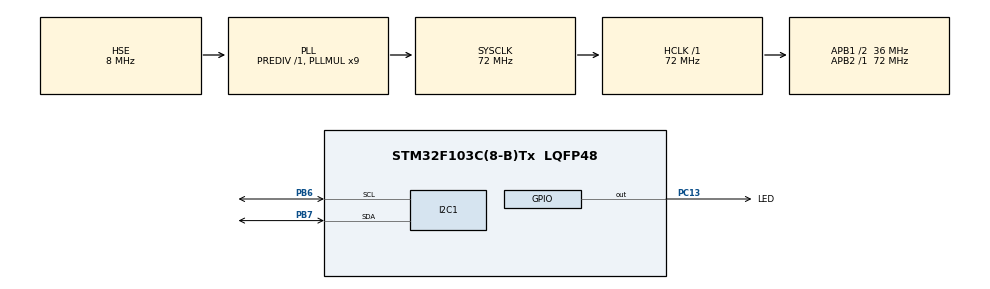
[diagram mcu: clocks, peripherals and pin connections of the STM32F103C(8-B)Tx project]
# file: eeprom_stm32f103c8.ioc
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I2C1.I2C_Mode=I2C_Fast
Mcu.Family=STM32F1
Mcu.Name=STM32F103C(8-B)Tx
Mcu.Package=LQFP48
NVIC.PriorityGroup=NVIC_PRIORITYGROUP_4
PA13.Mode=Serial_Wire
PA13.Signal=SYS_JTMS-SWDIO
PA14.Mode=Serial_Wire
PA14.Signal=SYS_JTCK-SWCLK
PB6.Mode=I2C
PB6.Signal=I2C1_SCL
PB7.Mode=I2C
PB7.Signal=I2C1_SDA
PC13-TAMPER-RTC.GPIO_Label=LED
PC13-TAMPER-RTC.PinState=GPIO_PIN_SET
PC13-TAMPER-RTC.Signal=GPIO_Output
PC14-OSC32_IN.Mode=LSE-External-Oscillator
PC14-OSC32_IN.Signal=RCC_OSC32_IN
PC15-OSC32_OUT.Mode=LSE-External-Oscillator
PC15-OSC32_OUT.Signal=RCC_OSC32_OUT
PD0-OSC_IN.Mode=HSE-External-Oscillator
PD0-OSC_IN.Signal=RCC_OSC_IN
PD1-OSC_OUT.Mode=HSE-External-Oscillator
PD1-OSC_OUT.Signal=RCC_OSC_OUT
ProjectManager.HeapSize=0x200
ProjectManager.StackSize=0x400
ProjectManager.TargetToolchain=STM32CubeIDE
RCC.AHBFreq_Value=72000000
RCC.APB1CLKDivider=RCC_HCLK_DIV2
RCC.APB1Freq_Value=36000000
RCC.APB1TimFreq_Value=72000000
RCC.APB2Freq_Value=72000000
RCC.APB2TimFreq_Value=72000000
RCC.HCLKFreq_Value=72000000
RCC.PLLMUL=RCC_PLL_MUL9
RCC.PLLSourceVirtual=RCC_PLLSOURCE_HSE
RCC.SYSCLKFreq_VALUE=72000000
RCC.SYSCLKSource=RCC_SYSCLKSOURCE_PLLCLK
RCC.USBFreq_Value=72000000
board=custom

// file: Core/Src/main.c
/* USER CODE BEGIN Header */
/**
 ******************************************************************************
 * @file           : main.c
 * @brief          : Example code to write and read data to 24LC02B EEPROM
 ******************************************************************************
 * Edit "eeprom_24LC02B.h" to use the i2c port setup in CubeMX on the device,
 * 	by default the port used is i2c1
 *
 * Write data then read back data from the eeprom. The return status of all write
 *  commands are saved in this code but it is not necessary. Write function
 *  returns 0 if data is written, returns 1 if data is already on eeprom so no overwrite,
 *  returns 2 if there is an error.
 *
 * Set a debug breakpoint at the while(1) loop so that after running the processor
 *  will pause and the memory can be inspected.
 *
 ******************************************************************************
 */
/* USER CODE END Header */

#include "main.h"
#include "i2c.h"
#include "gpio.h"

/* USER CODE BEGIN Includes */
#include "eeprom_24LC02B.h"

/* USER CODE END Includes */

/* USER CODE BEGIN PV */
uint8_t noMatchCount = 0; // keep track of times data_out != data_in

uint8_t data_addr = 0;	// first address to write below data to

uint8_t uint8_out = 189;
uint8_t uint8_in;
uint8_t uint8_status;

int8_t int8_out = -89;
int8_t int8_in;
uint8_t int8_status;

uint16_t uint16_out = 35987;
uint16_t uint16_in;
uint8_t uint16_status;

int16_t int16_out = -15976;
int16_t int16_in;
uint8_t int16_status;

uint32_t uint32_out = 789456123;
uint32_t uint32_in;
uint8_t uint32_status;

int32_t int32_out = -789123;
int32_t int32_in;
uint8_t int32_status;

float float_out = 69.1254;
float float_in;
uint8_t float_status;

double double_out = 7.648216478936315;
double double_in;
uint8_t double_status;

uint8_t str_out[] = "sdperry.com";
uint8_t str_in[sizeof(str_out)];
uint8_t str_status;

uint8_t buffer[255];

/* USER CODE END PV */

void SystemClock_Config(void);

int main(void) {

	/* MCU Configuration--------------------------------------------------------*/

	/* Reset of all peripherals, Initializes the Flash interface and the Systick. */
	HAL_Init();

	/* Configure the system clock */
	SystemClock_Config();

	/* Initialize all configured peripherals */
	MX_GPIO_Init();
	MX_I2C1_Init();
	/* USER CODE BEGIN 2 */
	// write uint8_t to eeprom, get the return status as uint8_status
	uint8_status = EEPROM_24LC02B_write_uint8(data_addr, &uint8_out);
	HAL_Delay(5);	// wait for eeprom to finish writing data
	uint8_in = EEPROM_24LC02B_read_uint8(data_addr); // read back data

	if (uint8_out != uint8_in) {
		noMatchCount++;
	}

	data_addr += sizeof(uint8_t);

	// write int8_t to eeprom, get the return status as int8_status
	int8_status = EEPROM_24LC02B_write_int8(data_addr, &int8_out);
	HAL_Delay(5);	// wait for eeprom to finish writing data
	int8_in = EEPROM_24LC02B_read_int8(data_addr); // read back data

	if (int8_out != int8_in) {
		noMatchCount++;
	}

	data_addr += sizeof(int8_t);

	// write uint16_t to eeprom, get the return status as uint16_status
	uint16_status = EEPROM_24LC02B_write_uint16(data_addr, &uint16_out);
	HAL_Delay(5);	// wait for eeprom to finish writing data
	uint16_in = EEPROM_24LC02B_read_uint16(data_addr);

	if (uint16_out != uint16_in) {
		noMatchCount++;
	}

	data_addr += sizeof(uint16_t);

	// write int16_t to eeprom, get the return status as int16_status
	int16_status = EEPROM_24LC02B_write_int16(data_addr, &int16_out);
	HAL_Delay(5);	// wait for eeprom to finish writing data
	int16_in = EEPROM_24LC02B_read_int16(data_addr);

	if (int16_out != int16_in) {
		noMatchCount++;
	}

	data_addr += sizeof(int16_t);

	// write uint32_t to eeprom, get the return status as uint32_status
	uint32_status = EEPROM_24LC02B_write_uint32(data_addr, &uint32_out);
	HAL_Delay(5);	// wait for eeprom to finish writing data
	uint32_in = EEPROM_24LC02B_read_uint32(data_addr);

	if (uint32_out != uint32_in) {
		noMatchCount++;
	}

	data_addr += sizeof(uint32_t);

	// write int32_t to eeprom, get the return status as int32_status
	int32_status = EEPROM_24LC02B_write_int32(data_addr, &int32_out);
	HAL_Delay(5);	// wait for eeprom to finish writing data
	int32_in = EEPROM_24LC02B_read_int32(data_addr);

	if (int32_out != int32_in) {
		noMatchCount++;
	}

	data_addr += sizeof(int32_t);

	// write float to eeprom, get the return status as float_status
	float_status = EEPROM_24LC02B_write_float(data_addr, &float_out);
	HAL_Delay(5);	// wait for eeprom to finish writing data
	float_in = EEPROM_24LC02B_read_float(data_addr);

	if (float_out != float_in) {
		noMatchCount++;
	}

	data_addr += sizeof(float);

	// write double to eeprom, get the return status as double_status
	double_status = EEPROM_24LC02B_write_double(data_addr, &double_out);
	HAL_Delay(5);	// wait for eeprom to finish writing data
	double_in = EEPROM_24LC02B_read_double(data_addr);

	if (double_out != double_in) {
		noMatchCount++;
	}

	data_addr += sizeof(double);

	// write char string to eeprom, get the return status as str_status
	str_status = EEPROM_24LC02B_write_str(data_addr, str_out, sizeof(str_out));
	HAL_Delay(5);	// wait for eeprom to finish writing data
	EEPROM_24LC02B_read_str(data_addr, str_in, sizeof(str_in));

	if(strcmp((char *) str_in, (char *) str_out)) {
		noMatchCount++;
	}

	// read the entire eeprom
	EEPROM_24LC02B_memdump(buffer, sizeof(buffer));

	if (noMatchCount != 0) {
		HAL_GPIO_WritePin(LED_GPIO_Port, LED_Pin, GPIO_PIN_RESET);
	}

	/* USER CODE END 2 */

	/* Infinite loop */
	while (1) {

	}
}

void SystemClock_Config(void) {
	RCC_OscInitTypeDef RCC_OscInitStruct = { 0 };
	RCC_ClkInitTypeDef RCC_ClkInitStruct = { 0 };

	/** Initializes the CPU, AHB and APB busses clocks
	 */
	RCC_OscInitStruct.OscillatorType = RCC_OSCILLATORTYPE_HSE;
	RCC_OscInitStruct.HSEState = RCC_HSE_ON;
	RCC_OscInitStruct.HSEPredivValue = RCC_HSE_PREDIV_DIV1;
	RCC_OscInitStruct.HSIState = RCC_HSI_ON;
	RCC_OscInitStruct.PLL.PLLState = RCC_PLL_ON;
	RCC_OscInitStruct.PLL.PLLSource = RCC_PLLSOURCE_HSE;
	RCC_OscInitStruct.PLL.PLLMUL = RCC_PLL_MUL9;
	if (HAL_RCC_OscConfig(&RCC_OscInitStruct) != HAL_OK) {
		Error_Handler();
	}
	/** Initializes the CPU, AHB and APB busses clocks
	 */
	RCC_ClkInitStruct.ClockType = RCC_CLOCKTYPE_HCLK | RCC_CLOCKTYPE_SYSCLK | RCC_CLOCKTYPE_PCLK1 | RCC_CLOCKTYPE_PCLK2;
	RCC_ClkInitStruct.SYSCLKSource = RCC_SYSCLKSOURCE_PLLCLK;
	RCC_ClkInitStruct.AHBCLKDivider = RCC_SYSCLK_DIV1;
	RCC_ClkInitStruct.APB1CLKDivider = RCC_HCLK_DIV2;
	RCC_ClkInitStruct.APB2CLKDivider = RCC_HCLK_DIV1;

	if (HAL_RCC_ClockConfig(&RCC_ClkInitStruct, FLASH_LATENCY_2) != HAL_OK) {
		Error_Handler();
	}
}

void Error_Handler(void) {
}

/************************ (C) COPYRIGHT STMicroelectronics *****END OF FILE****/
